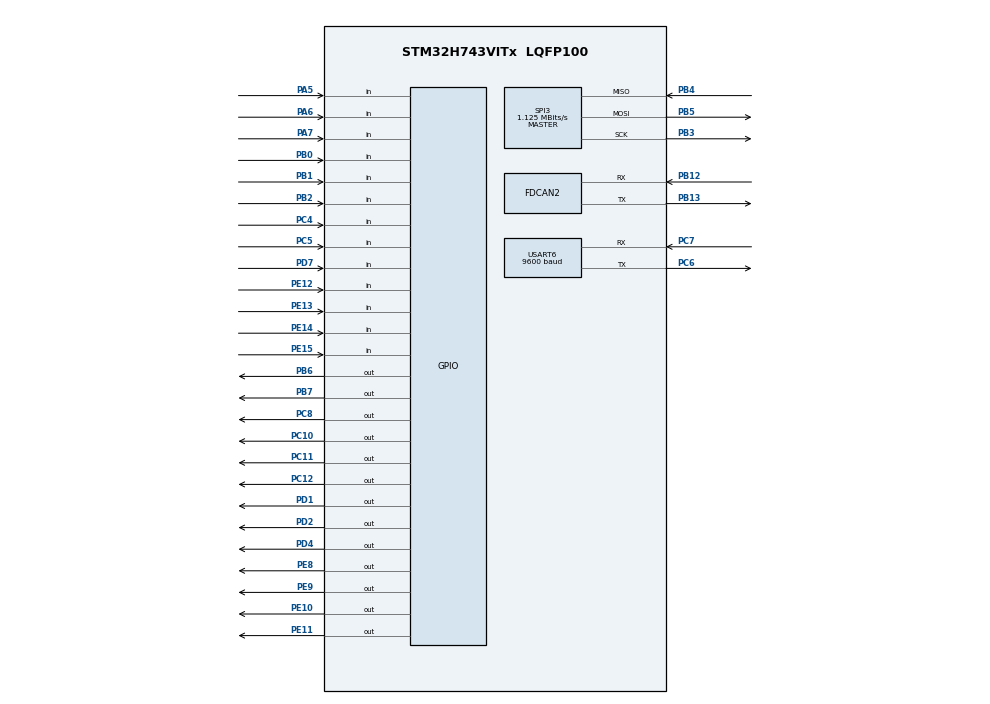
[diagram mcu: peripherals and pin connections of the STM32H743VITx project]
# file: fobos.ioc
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Dma.Request0=SPI3_TX
Dma.SPI3_TX.0.Direction=DMA_MEMORY_TO_PERIPH
Dma.SPI3_TX.0.EventEnable=DISABLE
Dma.SPI3_TX.0.FIFOMode=DMA_FIFOMODE_DISABLE
Dma.SPI3_TX.0.Instance=DMA1_Stream0
Dma.SPI3_TX.0.MemDataAlignment=DMA_MDATAALIGN_BYTE
Dma.SPI3_TX.0.MemInc=DMA_MINC_ENABLE
Dma.SPI3_TX.0.Mode=DMA_NORMAL
Dma.SPI3_TX.0.PeriphDataAlignment=DMA_PDATAALIGN_BYTE
Dma.SPI3_TX.0.PeriphInc=DMA_PINC_DISABLE
Dma.SPI3_TX.0.Polarity=HAL_DMAMUX_REQ_GEN_RISING
Dma.SPI3_TX.0.Priority=DMA_PRIORITY_LOW
Dma.SPI3_TX.0.RequestNumber=1
Dma.SPI3_TX.0.SyncEnable=DISABLE
Dma.SPI3_TX.0.SyncPolarity=HAL_DMAMUX_SYNC_NO_EVENT
Dma.SPI3_TX.0.SyncRequestNumber=1
FDCAN2.Init_ProtocolException=ENABLE
FDCAN2.NominalPrescaler=4
FDCAN2.NominalTimeSeg1=15
FDCAN2.RxBuffersNbr=1
FDCAN2.StdFiltersNbr=1
FDCAN2.TxBuffersNbr=1
FDCAN2.TxFifoQueueElmtsNbr=0
FDCAN2.TxFifoQueueMode=FDCAN_TX_QUEUE_OPERATION
FREERTOS.Tasks01=EthTask,0,1024,EthernetTask_func,Default,NULL,Dynamic,NULL,NULL;DigIOTask,-3,128,DigIOTask_func,Default,NULL,Dynamic,NULL,NULL
Mcu.Family=STM32H7
Mcu.Name=STM32H743VITx
Mcu.Package=LQFP100
NVIC.DMA1_Stream0_IRQn=true\:5\:0\:false\:false\:true\:true\:false
NVIC.PriorityGroup=NVIC_PRIORITYGROUP_4
NVIC.SPI3_IRQn=true\:5\:0\:false\:false\:true\:true\:false
NVIC.TIM7_IRQn=true\:5\:0\:false\:false\:true\:true\:true
PA13\ (JTMS/SWDIO).Mode=Serial_Wire
PA13\ (JTMS/SWDIO).Signal=SYS_JTMS-SWDIO
PA14\ (JTCK/SWCLK).Mode=Serial_Wire
PA14\ (JTCK/SWCLK).Signal=SYS_JTCK-SWCLK
PA5.Signal=GPIO_Input
PA6.Signal=GPIO_Input
PA7.Signal=GPIO_Input
PB0.Signal=GPIO_Input
PB1.Signal=GPIO_Input
PB12.Mode=FDCANSlave
PB12.Signal=FDCAN2_RX
PB13.Mode=FDCANSlave
PB13.Signal=FDCAN2_TX
PB2.Signal=GPIO_Input
PB3\ (JTDO/TRACESWO).GPIO_Mode=GPIO_MODE_AF_PP
PB3\ (JTDO/TRACESWO).GPIO_PuPd=GPIO_PULLDOWN
PB3\ (JTDO/TRACESWO).GPIO_Speed=GPIO_SPEED_FREQ_VERY_HIGH
PB3\ (JTDO/TRACESWO).Mode=Full_Duplex_Master
PB3\ (JTDO/TRACESWO).Signal=SPI3_SCK
PB4\ (NJTRST).GPIO_Mode=GPIO_MODE_AF_PP
PB4\ (NJTRST).GPIO_PuPd=GPIO_PULLDOWN
PB4\ (NJTRST).GPIO_Speed=GPIO_SPEED_FREQ_VERY_HIGH
PB4\ (NJTRST).Mode=Full_Duplex_Master
PB4\ (NJTRST).Signal=SPI3_MISO
PB5.GPIO_Mode=GPIO_MODE_AF_PP
PB5.GPIO_PuPd=GPIO_PULLDOWN
PB5.GPIO_Speed=GPIO_SPEED_FREQ_VERY_HIGH
PB5.Mode=Full_Duplex_Master
PB5.Signal=SPI3_MOSI
PB6.GPIO_FM6=SYSCFG_PMCR_I2C_PB6_FMP
PB6.GPIO_PuPd=GPIO_PULLDOWN
PB6.GPIO_Speed=GPIO_SPEED_FREQ_HIGH
PB6.Signal=GPIO_Output
PB7.Signal=GPIO_Output
PC10.GPIO_PuPd=GPIO_PULLDOWN
PC10.Signal=GPIO_Output
PC11.GPIO_PuPd=GPIO_PULLDOWN
PC11.Signal=GPIO_Output
PC12.GPIO_PuPd=GPIO_PULLDOWN
PC12.Signal=GPIO_Output
PC14-OSC32_IN\ (OSC32_IN).Mode=LSE-External-Oscillator
PC14-OSC32_IN\ (OSC32_IN).Signal=RCC_OSC32_IN
PC15-OSC32_OUT\ (OSC32_OUT).Mode=LSE-External-Oscillator
PC15-OSC32_OUT\ (OSC32_OUT).Signal=RCC_OSC32_OUT
PC4.Signal=GPIO_Input
PC5.Signal=GPIO_Input
PC6.Mode=Asynchronous
PC6.Signal=USART6_TX
PC7.Mode=Asynchronous
PC7.Signal=USART6_RX
PC8.GPIO_PuPd=GPIO_PULLDOWN
PC8.Signal=GPIO_Output
PD1.GPIO_PuPd=GPIO_PULLDOWN
PD1.Signal=GPIO_Output
PD2.GPIO_PuPd=GPIO_PULLDOWN
PD2.Signal=GPIO_Output
PD4.GPIO_PuPd=GPIO_PULLDOWN
PD4.Signal=GPIO_Output
PD7.GPIO_PuPd=GPIO_PULLDOWN
PD7.Signal=GPIO_Input
PE10.Signal=GPIO_Output
PE11.Signal=GPIO_Output
PE12.Signal=GPIO_Input
PE13.Signal=GPIO_Input
PE14.Signal=GPIO_Input
PE15.Signal=GPIO_Input
PE8.Signal=GPIO_Output
PE9.Signal=GPIO_Output
PH0-OSC_IN\ (PH0).Mode=HSE-External-Oscillator
PH0-OSC_IN\ (PH0).Signal=RCC_OSC_IN
PH1-OSC_OUT\ (PH1).Mode=HSE-External-Oscillator
PH1-OSC_OUT\ (PH1).Signal=RCC_OSC_OUT
ProjectManager.HeapSize=0x200
ProjectManager.StackSize=0x400
ProjectManager.TargetToolchain=TrueSTUDIO
RCC.ADCFreq_Value=75000000
RCC.APB1Freq_Value=36000000
RCC.APB2Freq_Value=9000000
RCC.APB3Freq_Value=9000000
RCC.APB4Freq_Value=9000000
RCC.CKPERSourceSelection=RCC_CLKPSOURCE_HSE
RCC.CortexFreq_Value=72000000
RCC.D1PPRE=RCC_APB3_DIV8
RCC.D2PPRE1=RCC_APB1_DIV2
RCC.D2PPRE2=RCC_APB2_DIV8
RCC.D3PPRE=RCC_APB4_DIV8
RCC.DIVM1=5
RCC.DIVM2=20
RCC.DIVM3=8
RCC.DIVN1=72
RCC.DIVN2=150
RCC.DIVN3=96
RCC.DIVP1=4
RCC.DIVP3=128
RCC.DIVQ1=8
RCC.DIVQ2=30
RCC.DIVQ3=5
RCC.HCLKFreq_Value=72000000
RCC.HSE_VALUE=20000000
RCC.PLLSourceVirtual=RCC_PLLSOURCE_HSE
RCC.SYSCLKFreq_VALUE=72000000
RCC.SYSCLKSource=RCC_SYSCLKSOURCE_PLLCLK
RCC.USART16CLockSelection=RCC_USART16CLKSOURCE_PLL2
RCC.USBCLockSelection=RCC_USBCLKSOURCE_PLL3
RCC.USBFreq_Value=48000000
SPI3.BaudRatePrescaler=SPI_BAUDRATEPRESCALER_32
SPI3.CalculateBaudRate=1.125 MBits/s
SPI3.DataSize=SPI_DATASIZE_8BIT
SPI3.Direction=SPI_DIRECTION_2LINES
SPI3.Mode=SPI_MODE_MASTER
SPI3.VirtualType=VM_MASTER
TIM7.Period=1500
TIM7.Prescaler=2000
USART6.BaudRate=9600
USART6.FIFOMode=FIFOMODE_DISABLE
USART6.VirtualMode=VM_ASYNC
VP_FREERTOS_VS_ENABLE.Mode=Enabled
VP_IWDG1_VS_IWDG.Mode=IWDG_Activate
VP_TIM7_VS_ClockSourceINT.Mode=Enable_Timer
board=custom

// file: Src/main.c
/* USER CODE BEGIN Header */
/**
  ******************************************************************************
  * @file           : main.c
  * @brief          : Main program body
  ******************************************************************************
  * This notice applies to any and all portions of this file
  * that are not between comment pairs USER CODE BEGIN and
  * USER CODE END. Other portions of this file, whether
  * inserted by the user or by software development tools
  * are owned by their respective copyright owners.
  *
  * Copyright (c) 2019 STMicroelectronics International N.V.
  * All rights reserved.
  *
  * Redistribution and use in source and binary forms, with or without
  * modification, are permitted, provided that the following conditions are met:
  *
  * 1. Redistribution of source code must retain the above copyright notice,
  *    this list of conditions and the following disclaimer.
  * 2. Redistributions in binary form must reproduce the above copyright notice,
  *    this list of conditions and the following disclaimer in the documentation
  *    and/or other materials provided with the distribution.
  * 3. Neither the name of STMicroelectronics nor the names of other
  *    contributors to this software may be used to endorse or promote products
  *    derived from this software without specific written permission.
  * 4. This software, including modifications and/or derivative works of this
  *    software, must execute solely and exclusively on microcontroller or
  *    microprocessor devices manufactured by or for STMicroelectronics.
  * 5. Redistribution and use of this software other than as permitted under
  *    this license is void and will automatically terminate your rights under
  *    this license.
  *
  * THIS SOFTWARE IS PROVIDED BY STMICROELECTRONICS AND CONTRIBUTORS "AS IS"
  * AND ANY EXPRESS, IMPLIED OR STATUTORY WARRANTIES, INCLUDING, BUT NOT
  * LIMITED TO, THE IMPLIED WARRANTIES OF MERCHANTABILITY, FITNESS FOR A
  * PARTICULAR PURPOSE AND NON-INFRINGEMENT OF THIRD PARTY INTELLECTUAL PROPERTY
  * RIGHTS ARE DISCLAIMED TO THE FULLEST EXTENT PERMITTED BY LAW. IN NO EVENT
  * SHALL STMICROELECTRONICS OR CONTRIBUTORS BE LIABLE FOR ANY DIRECT, INDIRECT,
  * INCIDENTAL, SPECIAL, EXEMPLARY, OR CONSEQUENTIAL DAMAGES (INCLUDING, BUT NOT
  * LIMITED TO, PROCUREMENT OF SUBSTITUTE GOODS OR SERVICES; LOSS OF USE, DATA,
  * OR PROFITS; OR BUSINESS INTERRUPTION) HOWEVER CAUSED AND ON ANY THEORY OF
  * LIABILITY, WHETHER IN CONTRACT, STRICT LIABILITY, OR TORT (INCLUDING
  * NEGLIGENCE OR OTHERWISE) ARISING IN ANY WAY OUT OF THE USE OF THIS SOFTWARE,
  * EVEN IF ADVISED OF THE POSSIBILITY OF SUCH DAMAGE.
  *
  ******************************************************************************
  */
/* USER CODE END Header */

#include "main.h"
#include "cmsis_os.h"

/* USER CODE BEGIN Includes */
#include "fobos_eth.h"
/* USER CODE END Includes */

FDCAN_HandleTypeDef hfdcan2;

IWDG_HandleTypeDef hiwdg1;

SPI_HandleTypeDef hspi3;
DMA_HandleTypeDef hdma_spi3_tx;

TIM_HandleTypeDef htim7;

UART_HandleTypeDef huart6;

osThreadId EthTaskHandle;
osThreadId DigIOTaskHandle;

void SystemClock_Config(void);
static void MX_GPIO_Init(void);
static void MX_DMA_Init(void);
static void MX_USART6_UART_Init(void);
static void MX_TIM7_Init(void);
static void MX_SPI3_Init(void);
static void MX_FDCAN2_Init(void);
static void MX_IWDG1_Init(void);
void EthernetTask_func(void const * argument);
void DigIOTask_func(void const * argument);

/* USER CODE BEGIN 0 */
#define LED_VD5(state)		HAL_GPIO_WritePin(GPIOC, GPIO_PIN_12, state)
#define LED_VD6(state)		HAL_GPIO_WritePin(GPIOC, GPIO_PIN_11, state)
#define LED_VD7(state)		HAL_GPIO_WritePin(GPIOC, GPIO_PIN_10, state)
/* USER CODE END 0 */

int main(void)
{

  /* MCU Configuration--------------------------------------------------------*/

  /* Reset of all peripherals, Initializes the Flash interface and the Systick. */
  HAL_Init();

  /* Configure the system clock */
  SystemClock_Config();

  /* Initialize all configured peripherals */
  MX_GPIO_Init();
  MX_DMA_Init();
  MX_USART6_UART_Init();
  MX_TIM7_Init();
  MX_SPI3_Init();
  MX_FDCAN2_Init();
  MX_IWDG1_Init();

  /* Create the thread(s) */
  /* definition and creation of EthTask */
  osThreadDef(EthTask, EthernetTask_func, osPriorityNormal, 0, 1024);
  EthTaskHandle = osThreadCreate(osThread(EthTask), NULL);

  /* definition and creation of DigIOTask */
  osThreadDef(DigIOTask, DigIOTask_func, osPriorityIdle, 0, 128);
  DigIOTaskHandle = osThreadCreate(osThread(DigIOTask), NULL);

  /* Start scheduler */
  osKernelStart();

  /* We should never get here as control is now taken by the scheduler */

  /* Infinite loop */
  while (1)
  {

  }
}

void SystemClock_Config(void)
{
  RCC_OscInitTypeDef RCC_OscInitStruct = {0};
  RCC_ClkInitTypeDef RCC_ClkInitStruct = {0};
  RCC_PeriphCLKInitTypeDef PeriphClkInitStruct = {0};

  /**Supply configuration update enable
  */
  MODIFY_REG(PWR->CR3, PWR_CR3_SCUEN, 0);
  /**Configure the main internal regulator output voltage
  */
  __HAL_PWR_VOLTAGESCALING_CONFIG(PWR_REGULATOR_VOLTAGE_SCALE3);

  while ((PWR->D3CR & (PWR_D3CR_VOSRDY)) != PWR_D3CR_VOSRDY)
  {

  }
  /**Macro to configure the PLL clock source
  */
  __HAL_RCC_PLL_PLLSOURCE_CONFIG(RCC_PLLSOURCE_HSE);
  /**Initializes the CPU, AHB and APB busses clocks
  */
  RCC_OscInitStruct.OscillatorType = RCC_OSCILLATORTYPE_LSI|RCC_OSCILLATORTYPE_HSE;
  RCC_OscInitStruct.HSEState = RCC_HSE_ON;
  RCC_OscInitStruct.LSIState = RCC_LSI_ON;
  RCC_OscInitStruct.PLL.PLLState = RCC_PLL_ON;
  RCC_OscInitStruct.PLL.PLLSource = RCC_PLLSOURCE_HSE;
  RCC_OscInitStruct.PLL.PLLM = 5;
  RCC_OscInitStruct.PLL.PLLN = 72;
  RCC_OscInitStruct.PLL.PLLP = 4;
  RCC_OscInitStruct.PLL.PLLQ = 8;
  RCC_OscInitStruct.PLL.PLLR = 2;
  RCC_OscInitStruct.PLL.PLLRGE = RCC_PLL1VCIRANGE_2;
  RCC_OscInitStruct.PLL.PLLVCOSEL = RCC_PLL1VCOWIDE;
  RCC_OscInitStruct.PLL.PLLFRACN = 0;
  if (HAL_RCC_OscConfig(&RCC_OscInitStruct) != HAL_OK)
  {
    Error_Handler();
  }
  /**Initializes the CPU, AHB and APB busses clocks
  */
  RCC_ClkInitStruct.ClockType = RCC_CLOCKTYPE_HCLK|RCC_CLOCKTYPE_SYSCLK
                              |RCC_CLOCKTYPE_PCLK1|RCC_CLOCKTYPE_PCLK2
                              |RCC_CLOCKTYPE_D3PCLK1|RCC_CLOCKTYPE_D1PCLK1;
  RCC_ClkInitStruct.SYSCLKSource = RCC_SYSCLKSOURCE_PLLCLK;
  RCC_ClkInitStruct.SYSCLKDivider = RCC_SYSCLK_DIV1;
  RCC_ClkInitStruct.AHBCLKDivider = RCC_HCLK_DIV1;
  RCC_ClkInitStruct.APB3CLKDivider = RCC_APB3_DIV8;
  RCC_ClkInitStruct.APB1CLKDivider = RCC_APB1_DIV2;
  RCC_ClkInitStruct.APB2CLKDivider = RCC_APB2_DIV8;
  RCC_ClkInitStruct.APB4CLKDivider = RCC_APB4_DIV8;

  if (HAL_RCC_ClockConfig(&RCC_ClkInitStruct, FLASH_LATENCY_1) != HAL_OK)
  {
    Error_Handler();
  }
  PeriphClkInitStruct.PeriphClockSelection = RCC_PERIPHCLK_USART6|RCC_PERIPHCLK_FDCAN
                              |RCC_PERIPHCLK_SPI3;
  PeriphClkInitStruct.PLL2.PLL2M = 20;
  PeriphClkInitStruct.PLL2.PLL2N = 150;
  PeriphClkInitStruct.PLL2.PLL2P = 2;
  PeriphClkInitStruct.PLL2.PLL2Q = 30;
  PeriphClkInitStruct.PLL2.PLL2R = 2;
  PeriphClkInitStruct.PLL2.PLL2RGE = RCC_PLL2VCIRANGE_0;
  PeriphClkInitStruct.PLL2.PLL2VCOSEL = RCC_PLL2VCOMEDIUM;
  PeriphClkInitStruct.PLL2.PLL2FRACN = 0;
  PeriphClkInitStruct.Spi123ClockSelection = RCC_SPI123CLKSOURCE_PLL;
  PeriphClkInitStruct.FdcanClockSelection = RCC_FDCANCLKSOURCE_PLL;
  PeriphClkInitStruct.Usart16ClockSelection = RCC_USART16CLKSOURCE_PLL2;
  if (HAL_RCCEx_PeriphCLKConfig(&PeriphClkInitStruct) != HAL_OK)
  {
    Error_Handler();
  }
}

static void MX_FDCAN2_Init(void)
{

  hfdcan2.Instance = FDCAN2;
  hfdcan2.Init.FrameFormat = FDCAN_FRAME_CLASSIC;
  hfdcan2.Init.Mode = FDCAN_MODE_NORMAL;
  hfdcan2.Init.AutoRetransmission = DISABLE;
  hfdcan2.Init.TransmitPause = DISABLE;
  hfdcan2.Init.NominalPrescaler = 4;
  hfdcan2.Init.NominalSyncJumpWidth = 1;
  hfdcan2.Init.NominalTimeSeg1 = 15;
  hfdcan2.Init.NominalTimeSeg2 = 2;
  hfdcan2.Init.DataPrescaler = 1;
  hfdcan2.Init.DataSyncJumpWidth = 1;
  hfdcan2.Init.DataTimeSeg1 = 1;
  hfdcan2.Init.DataTimeSeg2 = 1;
  hfdcan2.Init.MessageRAMOffset = 0;
  hfdcan2.Init.StdFiltersNbr = 1;
  hfdcan2.Init.ExtFiltersNbr = 0;
  hfdcan2.Init.RxFifo0ElmtsNbr = 0;
  hfdcan2.Init.RxFifo0ElmtSize = FDCAN_DATA_BYTES_8;
  hfdcan2.Init.RxFifo1ElmtsNbr = 0;
  hfdcan2.Init.RxFifo1ElmtSize = FDCAN_DATA_BYTES_8;
  hfdcan2.Init.RxBuffersNbr = 1;
  hfdcan2.Init.RxBufferSize = FDCAN_DATA_BYTES_8;
  hfdcan2.Init.TxEventsNbr = 0;
  hfdcan2.Init.TxBuffersNbr = 1;
  hfdcan2.Init.TxFifoQueueElmtsNbr = 0;
  hfdcan2.Init.TxFifoQueueMode = FDCAN_TX_QUEUE_OPERATION;
  hfdcan2.Init.TxElmtSize = FDCAN_DATA_BYTES_8;
  hfdcan2.msgRam.StandardFilterSA = 0;
  hfdcan2.msgRam.ExtendedFilterSA = 0;
  hfdcan2.msgRam.RxFIFO0SA = 0;
  hfdcan2.msgRam.RxFIFO1SA = 0;
  hfdcan2.msgRam.RxBufferSA = 0;
  hfdcan2.msgRam.TxEventFIFOSA = 0;
  hfdcan2.msgRam.TxBufferSA = 0;
  hfdcan2.msgRam.TxFIFOQSA = 0;
  hfdcan2.msgRam.TTMemorySA = 0;
  hfdcan2.msgRam.EndAddress = 0;
  hfdcan2.ErrorCode = 0;
  if (HAL_FDCAN_Init(&hfdcan2) != HAL_OK)
  {
    Error_Handler();
  }

}

static void MX_IWDG1_Init(void)
{

  hiwdg1.Instance = IWDG1;
  hiwdg1.Init.Prescaler = IWDG_PRESCALER_64;
  hiwdg1.Init.Window = 4095;
  hiwdg1.Init.Reload = 400;//~750ms
  if (HAL_IWDG_Init(&hiwdg1) != HAL_OK)
  {
    Error_Handler();
  }
  /* USER CODE BEGIN IWDG1_Init 2 */
  //hiwdg1.Init.Reload = 400;//~780ms! 64 presc
  /* USER CODE END IWDG1_Init 2 */

}

static void MX_SPI3_Init(void)
{

  /* SPI3 parameter configuration*/
  hspi3.Instance = SPI3;
  hspi3.Init.Mode = SPI_MODE_MASTER;
  hspi3.Init.Direction = SPI_DIRECTION_2LINES;
  hspi3.Init.DataSize = SPI_DATASIZE_8BIT;
  hspi3.Init.CLKPolarity = SPI_POLARITY_LOW;
  hspi3.Init.CLKPhase = SPI_PHASE_1EDGE;
  hspi3.Init.NSS = SPI_NSS_SOFT;
  hspi3.Init.BaudRatePrescaler = SPI_BAUDRATEPRESCALER_32;
  hspi3.Init.FirstBit = SPI_FIRSTBIT_MSB;
  hspi3.Init.TIMode = SPI_TIMODE_DISABLE;
  hspi3.Init.CRCCalculation = SPI_CRCCALCULATION_DISABLE;
  hspi3.Init.CRCPolynomial = 7;
  hspi3.Init.NSSPMode = SPI_NSS_PULSE_ENABLE;
  hspi3.Init.NSSPolarity = SPI_NSS_POLARITY_LOW;
  hspi3.Init.FifoThreshold = SPI_FIFO_THRESHOLD_01DATA;
  hspi3.Init.TxCRCInitializationPattern = SPI_CRC_INITIALIZATION_ALL_ZERO_PATTERN;
  hspi3.Init.RxCRCInitializationPattern = SPI_CRC_INITIALIZATION_ALL_ZERO_PATTERN;
  hspi3.Init.MasterSSIdleness = SPI_MASTER_SS_IDLENESS_00CYCLE;
  hspi3.Init.MasterInterDataIdleness = SPI_MASTER_INTERDATA_IDLENESS_00CYCLE;
  hspi3.Init.MasterReceiverAutoSusp = SPI_MASTER_RX_AUTOSUSP_DISABLE;
  hspi3.Init.MasterKeepIOState = SPI_MASTER_KEEP_IO_STATE_DISABLE;
  hspi3.Init.IOSwap = SPI_IO_SWAP_DISABLE;
  if (HAL_SPI_Init(&hspi3) != HAL_OK)
  {
    Error_Handler();
  }

}

static void MX_TIM7_Init(void)
{

  TIM_MasterConfigTypeDef sMasterConfig = {0};

  htim7.Instance = TIM7;
  htim7.Init.Prescaler = 2000;
  htim7.Init.CounterMode = TIM_COUNTERMODE_UP;
  htim7.Init.Period = 1500;
  htim7.Init.AutoReloadPreload = TIM_AUTORELOAD_PRELOAD_DISABLE;
  if (HAL_TIM_Base_Init(&htim7) != HAL_OK)
  {
    Error_Handler();
  }
  sMasterConfig.MasterOutputTrigger = TIM_TRGO_RESET;
  sMasterConfig.MasterSlaveMode = TIM_MASTERSLAVEMODE_DISABLE;
  if (HAL_TIMEx_MasterConfigSynchronization(&htim7, &sMasterConfig) != HAL_OK)
  {
    Error_Handler();
  }

}

static void MX_USART6_UART_Init(void)
{

  huart6.Instance = USART6;
  huart6.Init.BaudRate = 9600;
  huart6.Init.WordLength = UART_WORDLENGTH_8B;
  huart6.Init.StopBits = UART_STOPBITS_1;
  huart6.Init.Parity = UART_PARITY_NONE;
  huart6.Init.Mode = UART_MODE_TX_RX;
  huart6.Init.HwFlowCtl = UART_HWCONTROL_NONE;
  huart6.Init.OverSampling = UART_OVERSAMPLING_16;
  huart6.Init.OneBitSampling = UART_ONE_BIT_SAMPLE_DISABLE;
  huart6.Init.Prescaler = UART_PRESCALER_DIV1;
  huart6.Init.FIFOMode = UART_FIFOMODE_DISABLE;
  huart6.Init.TXFIFOThreshold = UART_TXFIFO_THRESHOLD_1_8;
  huart6.Init.RXFIFOThreshold = UART_RXFIFO_THRESHOLD_1_8;
  huart6.AdvancedInit.AdvFeatureInit = UART_ADVFEATURE_NO_INIT;
  if (HAL_UART_Init(&huart6) != HAL_OK)
  {
    Error_Handler();
  }

}

static void MX_DMA_Init(void)
{
  /* DMA controller clock enable */
  __HAL_RCC_DMA1_CLK_ENABLE();

  /* DMA interrupt init */
  /* DMA1_Stream0_IRQn interrupt configuration */
  HAL_NVIC_SetPriority(DMA1_Stream0_IRQn, 5, 0);
  HAL_NVIC_EnableIRQ(DMA1_Stream0_IRQn);

}

static void MX_GPIO_Init(void)
{
  GPIO_InitTypeDef GPIO_InitStruct = {0};

  /* GPIO Ports Clock Enable */
  __HAL_RCC_GPIOC_CLK_ENABLE();
  __HAL_RCC_GPIOH_CLK_ENABLE();
  __HAL_RCC_GPIOA_CLK_ENABLE();
  __HAL_RCC_GPIOB_CLK_ENABLE();
  __HAL_RCC_GPIOE_CLK_ENABLE();
  __HAL_RCC_GPIOD_CLK_ENABLE();

  /*Configure GPIO pin Output Level */
  HAL_GPIO_WritePin(GPIOE, GPIO_PIN_8|GPIO_PIN_9|GPIO_PIN_10|GPIO_PIN_11, GPIO_PIN_RESET);

  /*Configure GPIO pin Output Level */
  HAL_GPIO_WritePin(GPIOC, GPIO_PIN_8|GPIO_PIN_10|GPIO_PIN_11|GPIO_PIN_12, GPIO_PIN_RESET);

  /*Configure GPIO pin Output Level */
  HAL_GPIO_WritePin(GPIOD, GPIO_PIN_1|GPIO_PIN_2|GPIO_PIN_4, GPIO_PIN_RESET);

  /*Configure GPIO pin Output Level */
  HAL_GPIO_WritePin(GPIOB, GPIO_PIN_6|GPIO_PIN_7, GPIO_PIN_RESET);

  /*Configure GPIO pins : PA5 PA6 PA7 */
  GPIO_InitStruct.Pin = GPIO_PIN_5|GPIO_PIN_6|GPIO_PIN_7;
  GPIO_InitStruct.Mode = GPIO_MODE_INPUT;
  GPIO_InitStruct.Pull = GPIO_NOPULL;
  HAL_GPIO_Init(GPIOA, &GPIO_InitStruct);

  /*Configure GPIO pins : PC4 PC5 */
  GPIO_InitStruct.Pin = GPIO_PIN_4|GPIO_PIN_5;
  GPIO_InitStruct.Mode = GPIO_MODE_INPUT;
  GPIO_InitStruct.Pull = GPIO_NOPULL;
  HAL_GPIO_Init(GPIOC, &GPIO_InitStruct);

  /*Configure GPIO pins : PB0 PB1 PB2 */
  GPIO_InitStruct.Pin = GPIO_PIN_0|GPIO_PIN_1|GPIO_PIN_2;
  GPIO_InitStruct.Mode = GPIO_MODE_INPUT;
  GPIO_InitStruct.Pull = GPIO_NOPULL;
  HAL_GPIO_Init(GPIOB, &GPIO_InitStruct);

  /*Configure GPIO pins : PE8 PE9 PE10 PE11 */
  GPIO_InitStruct.Pin = GPIO_PIN_8|GPIO_PIN_9|GPIO_PIN_10|GPIO_PIN_11;
  GPIO_InitStruct.Mode = GPIO_MODE_OUTPUT_PP;
  GPIO_InitStruct.Pull = GPIO_NOPULL;
  GPIO_InitStruct.Speed = GPIO_SPEED_FREQ_LOW;
  HAL_GPIO_Init(GPIOE, &GPIO_InitStruct);

  /*Configure GPIO pins : PE12 PE13 PE14 PE15 */
  GPIO_InitStruct.Pin = GPIO_PIN_12|GPIO_PIN_13|GPIO_PIN_14|GPIO_PIN_15;
  GPIO_InitStruct.Mode = GPIO_MODE_INPUT;
  GPIO_InitStruct.Pull = GPIO_NOPULL;
  HAL_GPIO_Init(GPIOE, &GPIO_InitStruct);

  /*Configure GPIO pins : PC8 PC10 PC11 PC12 */
  GPIO_InitStruct.Pin = GPIO_PIN_8|GPIO_PIN_10|GPIO_PIN_11|GPIO_PIN_12;
  GPIO_InitStruct.Mode = GPIO_MODE_OUTPUT_PP;
  GPIO_InitStruct.Pull = GPIO_PULLDOWN;
  GPIO_InitStruct.Speed = GPIO_SPEED_FREQ_LOW;
  HAL_GPIO_Init(GPIOC, &GPIO_InitStruct);

  /*Configure GPIO pins : PD1 PD2 PD4 */
  GPIO_InitStruct.Pin = GPIO_PIN_1|GPIO_PIN_2|GPIO_PIN_4;
  GPIO_InitStruct.Mode = GPIO_MODE_OUTPUT_PP;
  GPIO_InitStruct.Pull = GPIO_PULLDOWN;
  GPIO_InitStruct.Speed = GPIO_SPEED_FREQ_LOW;
  HAL_GPIO_Init(GPIOD, &GPIO_InitStruct);

  /*Configure GPIO pin : PD7 */
  GPIO_InitStruct.Pin = GPIO_PIN_7;
  GPIO_InitStruct.Mode = GPIO_MODE_INPUT;
  GPIO_InitStruct.Pull = GPIO_PULLDOWN;
  HAL_GPIO_Init(GPIOD, &GPIO_InitStruct);

  /*Configure GPIO pin : PB6 */
  GPIO_InitStruct.Pin = GPIO_PIN_6;
  GPIO_InitStruct.Mode = GPIO_MODE_OUTPUT_PP;
  GPIO_InitStruct.Pull = GPIO_PULLDOWN;
  GPIO_InitStruct.Speed = GPIO_SPEED_FREQ_HIGH;
  HAL_GPIO_Init(GPIOB, &GPIO_InitStruct);

  /*Configure GPIO pin : PB7 */
  GPIO_InitStruct.Pin = GPIO_PIN_7;
  GPIO_InitStruct.Mode = GPIO_MODE_OUTPUT_PP;
  GPIO_InitStruct.Pull = GPIO_NOPULL;
  GPIO_InitStruct.Speed = GPIO_SPEED_FREQ_LOW;
  HAL_GPIO_Init(GPIOB, &GPIO_InitStruct);

  /**/
  HAL_I2CEx_EnableFastModePlus(SYSCFG_PMCR_I2C_PB6_FMP);

}

void DigIOTask_func(void const * argument)
{
  /* USER CODE BEGIN DigIOTask_func */
	vTaskDelay(250);
	LED_VD5(SET);
	LED_VD6(SET);
	LED_VD7(SET);
  /* Infinite loop */
  for(;;)
  {
	  //HAL_IWDG_Refresh(&hiwdg1);
    osDelay(1);
  }
  /* USER CODE END DigIOTask_func */
}

void Error_Handler(void)
{
}

/************************ (C) COPYRIGHT STMicroelectronics *****END OF FILE****/
